# VPAC0_HTS_S_VBUSP register map
Vendor: Texas Instruments
Peripheral module from a debugger description file (folder J7ES).
Registers are 32-bit, read-write, reset 0x0 unless marked. A register's access mark holds for its fields unless they carry their own. Offsets are as the file gives them; lines under a group give offsets from that group; [hi:lo] are bit positions; {n}, {i} and the like mark numbered series; 'fields as' and 'values as' point back to an identical list; <NAME> marks a mode.

## VPAC0_HTS_S_VBUSP (part 1 of 2)
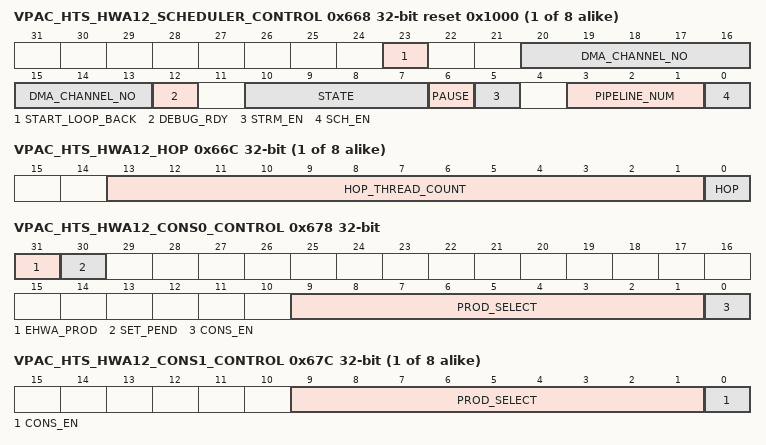
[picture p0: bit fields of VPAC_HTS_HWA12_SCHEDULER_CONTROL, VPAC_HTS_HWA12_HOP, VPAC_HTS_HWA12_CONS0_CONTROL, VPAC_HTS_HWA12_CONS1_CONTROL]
{0x188+0x68*i} VPAC_HTS_HWA{i}_SCHEDULER_CONTROL access per field reset 0x1000 (i=12..19) — Scheduler Control Register
  [23] START_LOOP_BACK rw — '1' -&gt; loop back start onto done in same cycle w/o asserting external channel start, '0' No loop back
  [20:13] DMA_CHANNEL_NO rw — DMA channel number for thread scheduler for HWA{i}
  [12] DEBUG_RDY rw — '0' -&gt; HWA{i} Scheduler resources must not be read during halted state.
  [10:7] STATE ro — Current state of HWA{i} Scheduler
  [6] PAUSE rw — '1' -&gt; pause/suspend scheduler , '0' -&gt; resume scheduler
  [5] STRM_EN rw — '1' -&gt; Streaming input enable, '0' No streaming input
  [3:1] PIPELINE_NUM rw — Pipeline Number of HWA{i} Scheduler
  [0] SCH_EN rw — scheduler enable
{0x18C+0x68*i} VPAC_HTS_HWA{i}_HOP (i=12..19) — Scheduler HOP Control Register. Help in detecting eop within scheduler. Once configured, it counts task/channel starts and stops issuing further starts. Specifically useful for Head of pipe dma scheduler .
  [13:1] HOP_THREAD_COUNT — Number of Task count for Head of pipe
  [0] HOP — '1' -&gt; Head of Pipe producer Sch , '0' -&gt; No hop
0x678 VPAC_HTS_HWA12_CONS0_CONTROL access per field — Controlling consumer socket 0 for HWA12
  [31] EHWA_PROD rw — '1' -&gt; spare consumer is connected to external host producer , '0' --&gt; no external host producer
  [30] SET_PEND wo — writing '1' sets pend on consumer socket
  [9:1] PROD_SELECT rw — producer select for HWA12 cons socket 0
  [0] CONS_EN rw — '1' -&gt; Consumer socket 0 enable , '0' Disable
{0x19C+0x68*i} VPAC_HTS_HWA{i}_CONS1_CONTROL (i=12..19) — Controlling consumer socket 1 for HWA{i}
  [9:1] PROD_SELECT — producer select for HWA{i} cons socket 1
  [0] CONS_EN — '1' -&gt; Consumer socket 1 enable , '0' Disable
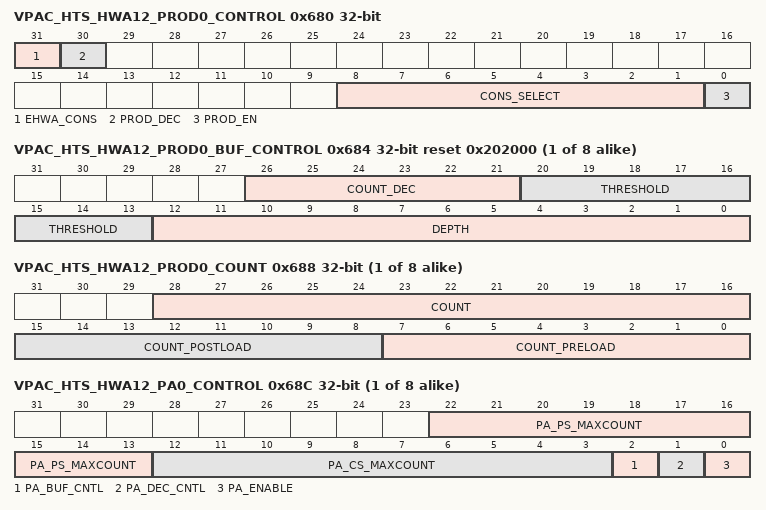
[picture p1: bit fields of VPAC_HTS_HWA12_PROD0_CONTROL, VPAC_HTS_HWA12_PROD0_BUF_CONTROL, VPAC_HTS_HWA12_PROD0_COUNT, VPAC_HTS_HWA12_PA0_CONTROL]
0x680 VPAC_HTS_HWA12_PROD0_CONTROL access per field — Controlling producer socket0 for HWA12
  [31] EHWA_CONS rw — '1' -&gt; spare consumer is connected to external host consumer , '0' --&gt; no external host consumer
  [30] PROD_DEC wo — writing '1' decrement prod count value
  [8:1] CONS_SELECT rw — consumer select for HWA12 prod socket 0.
  [0] PROD_EN rw — '1' -&gt; Producer socket 0 enable , '0' Disable
{0x1A4+0x68*i} VPAC_HTS_HWA{i}_PROD0_BUF_CONTROL reset 0x202000 (i=12..19) — Controlling producer socket0 buffer for HWA{i}
  [26:21] COUNT_DEC — Count decrement value for prod count
  [20:13] THRESHOLD — Count threshold to generate pend for consumer
  [12:0] DEPTH — Maximum number of producer buffer count
{0x1A8+0x68*i} VPAC_HTS_HWA{i}_PROD0_COUNT access per field (i=12..19) — Defining count values for pre/post load for generating pend by HWA{i} prod0
  [28:16] COUNT ro — current count value
  [15:8] COUNT_POSTLOAD rw — count postload after producer max thread count reached
  [7:0] COUNT_PRELOAD rw — count preload after scheduler start/init
{0x1AC+0x68*i} VPAC_HTS_HWA{i}_PA0_CONTROL (i=12..19) — control register to manage pattern adapter on HWA{i} prod socket0
  [22:13] PA_PS_MAXCOUNT — destination count for pattern adaptation (N), M --&gt; N
  [12:3] PA_CS_MAXCOUNT — source count for pattern adaptation (M), M --&gt; N
  [2] PA_BUF_CNTL — '1' -&gt; Apply threshold, count_preload and count_postload on pattern adapter count (use this only when pa_enable='1') '0' -&gt; Apply threshold, count_preload and count_postload on prod count (same behavior as if no pattern adapter.
  [1] PA_DEC_CNTL — '1' -&gt; post pattern adaptation, decrement ps count by count_dec , '0' -&gt; post pattern adaptation, decrement ps count by pa_cs_maxcount
  [0] PA_ENABLE — '1' -&gt; pa enable, '0' -&gt; disable
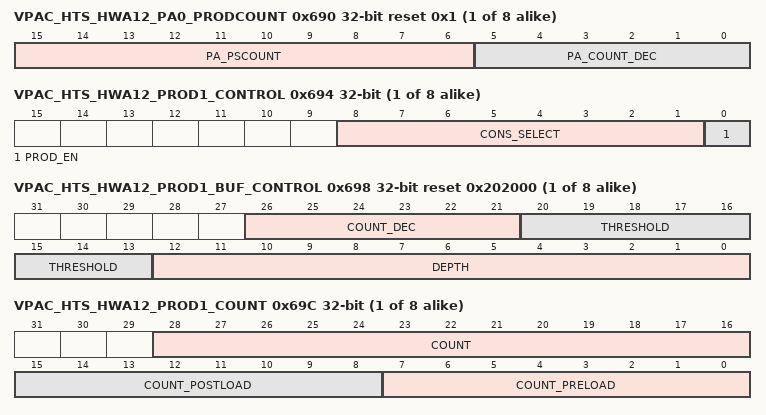
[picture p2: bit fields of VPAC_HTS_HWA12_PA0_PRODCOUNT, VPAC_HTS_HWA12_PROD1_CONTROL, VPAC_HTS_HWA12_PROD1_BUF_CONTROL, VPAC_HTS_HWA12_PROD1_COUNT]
{0x1B0+0x68*i} VPAC_HTS_HWA{i}_PA0_PRODCOUNT access per field reset 0x1 (i=12..19) — count values for HWA{i} prod socket0
  [15:6] PA_PSCOUNT ro — current count value of pa prod count
  [5:0] PA_COUNT_DEC rw — Decrement count value of pa_prod_count after pattern adapter prod count reaches threshold
{0x1B4+0x68*i} VPAC_HTS_HWA{i}_PROD1_CONTROL (i=12..19) — Controlling producer socket1 for HWA{i}
  [8:1] CONS_SELECT — consumer select for HWA{i} prod socket 1.
  [0] PROD_EN — '1' -&gt; Producer socket 0 enable , '0' Disable
{0x1B8+0x68*i} VPAC_HTS_HWA{i}_PROD1_BUF_CONTROL reset 0x202000 (i=12..19) — Controlling producer socket1 buffer for HWA{i}
  fields as VPAC_HTS_HWA12_PROD0_BUF_CONTROL
{0x1BC+0x68*i} VPAC_HTS_HWA{i}_PROD1_COUNT access per field (i=12..19) — Defining count values for pre/post load for generating pend by HWA{i} prod1
  fields as VPAC_HTS_HWA12_PROD0_COUNT
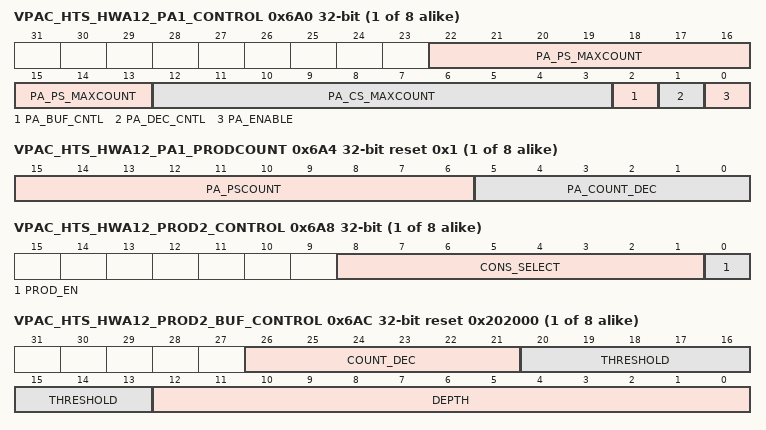
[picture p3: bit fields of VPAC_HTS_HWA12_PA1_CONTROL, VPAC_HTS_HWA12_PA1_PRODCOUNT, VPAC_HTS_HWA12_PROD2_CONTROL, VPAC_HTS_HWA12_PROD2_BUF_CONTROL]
{0x1C0+0x68*i} VPAC_HTS_HWA{i}_PA1_CONTROL (i=12..19) — control register to manage pattern adapter on HWA{i} prod socket1
  fields as VPAC_HTS_HWA12_PA0_CONTROL
{0x1C4+0x68*i} VPAC_HTS_HWA{i}_PA1_PRODCOUNT access per field reset 0x1 (i=12..19) — count values for HWA{i} prod socket1
  fields as VPAC_HTS_HWA12_PA0_PRODCOUNT
{0x1C8+0x68*i} VPAC_HTS_HWA{i}_PROD2_CONTROL (i=12..19) — Controlling producer socket2 for HWA{i}
  [8:1] CONS_SELECT — consumer select for HWA{i} prod socket 2.
  [0] PROD_EN — '1' -&gt; Producer socket 0 enable , '0' Disable
{0x1CC+0x68*i} VPAC_HTS_HWA{i}_PROD2_BUF_CONTROL reset 0x202000 (i=12..19) — Controlling producer socket2 buffer for HWA{i}
  fields as VPAC_HTS_HWA12_PROD0_BUF_CONTROL
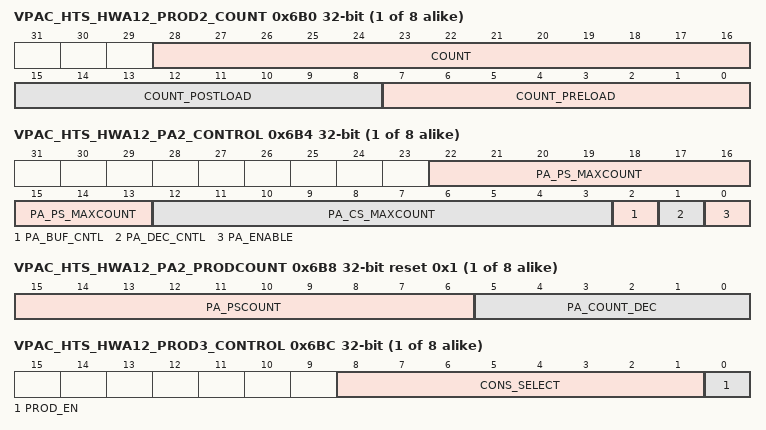
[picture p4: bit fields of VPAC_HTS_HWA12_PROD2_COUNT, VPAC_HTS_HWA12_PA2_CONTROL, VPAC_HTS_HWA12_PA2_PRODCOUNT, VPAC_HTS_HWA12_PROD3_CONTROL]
{0x1D0+0x68*i} VPAC_HTS_HWA{i}_PROD2_COUNT access per field (i=12..19) — Defining count values for pre/post load for generating pend by HWA{i} prod2
  fields as VPAC_HTS_HWA12_PROD0_COUNT
{0x1D4+0x68*i} VPAC_HTS_HWA{i}_PA2_CONTROL (i=12..19) — control register to manage pattern adapter on HWA{i} prod socket2
  fields as VPAC_HTS_HWA12_PA0_CONTROL
{0x1D8+0x68*i} VPAC_HTS_HWA{i}_PA2_PRODCOUNT access per field reset 0x1 (i=12..19) — count values for HWA{i} prod socket2
  fields as VPAC_HTS_HWA12_PA0_PRODCOUNT
{0x1DC+0x68*i} VPAC_HTS_HWA{i}_PROD3_CONTROL (i=12..19) — Controlling producer socket3 for HWA{i}
  [8:1] CONS_SELECT — consumer select for HWA{i} prod socket 3.
  [0] PROD_EN — '1' -&gt; Producer socket 0 enable , '0' Disable
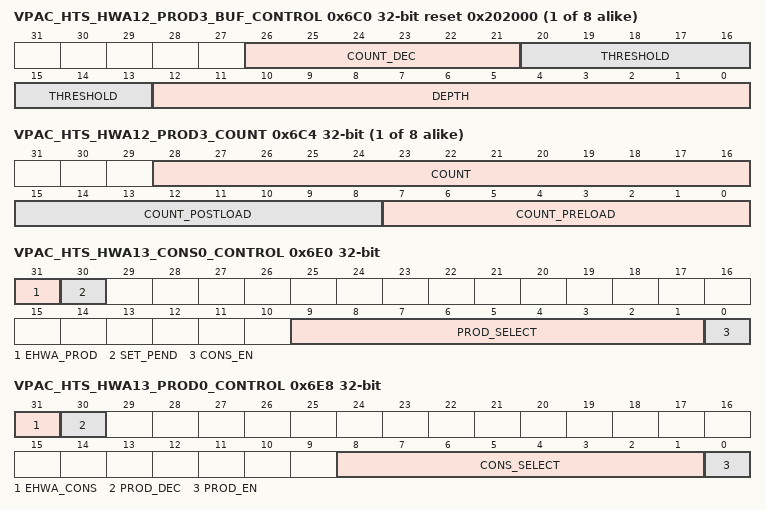
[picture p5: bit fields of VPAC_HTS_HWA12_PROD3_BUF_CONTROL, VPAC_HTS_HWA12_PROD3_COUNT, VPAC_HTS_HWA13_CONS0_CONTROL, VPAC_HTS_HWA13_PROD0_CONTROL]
{0x1E0+0x68*i} VPAC_HTS_HWA{i}_PROD3_BUF_CONTROL reset 0x202000 (i=12..19) — Controlling producer socket3 buffer for HWA{i}
  fields as VPAC_HTS_HWA12_PROD0_BUF_CONTROL
{0x1E4+0x68*i} VPAC_HTS_HWA{i}_PROD3_COUNT access per field (i=12..19) — Defining count values for pre/post load for generating pend by HWA{i} prod3
  fields as VPAC_HTS_HWA12_PROD0_COUNT
0x6E0 VPAC_HTS_HWA13_CONS0_CONTROL access per field — Controlling consumer socket 0 for HWA13
  [31] EHWA_PROD rw — '1' -&gt; spare consumer is connected to external host producer , '0' --&gt; no external host producer
  [30] SET_PEND wo — writing '1' sets pend on consumer socket
  [9:1] PROD_SELECT rw — producer select for HWA13 cons socket 0
  [0] CONS_EN rw — '1' -&gt; Consumer socket 0 enable , '0' Disable
0x6E8 VPAC_HTS_HWA13_PROD0_CONTROL access per field — Controlling producer socket0 for HWA13
  [31] EHWA_CONS rw — '1' -&gt; spare consumer is connected to external host consumer , '0' --&gt; no external host consumer
  [30] PROD_DEC wo — writing '1' decrement prod count value
  [8:1] CONS_SELECT rw — consumer select for HWA13 prod socket 0.
  [0] PROD_EN rw — '1' -&gt; Producer socket 0 enable , '0' Disable
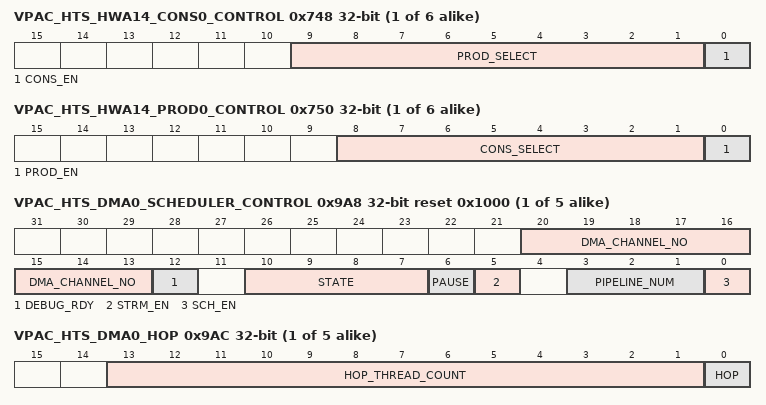
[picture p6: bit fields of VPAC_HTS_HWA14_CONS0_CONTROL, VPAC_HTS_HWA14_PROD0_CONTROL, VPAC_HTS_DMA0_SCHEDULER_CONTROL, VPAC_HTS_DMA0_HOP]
{0x198+0x68*i} VPAC_HTS_HWA{i}_CONS0_CONTROL (i=14..19) — Controlling consumer socket 0 for HWA{i}
  [9:1] PROD_SELECT — producer select for HWA{i} cons socket 0
  [0] CONS_EN — '1' -&gt; Consumer socket 0 enable , '0' Disable
{0x1A0+0x68*i} VPAC_HTS_HWA{i}_PROD0_CONTROL (i=14..19) — Controlling producer socket0 for HWA{i}
  [8:1] CONS_SELECT — consumer select for HWA{i} prod socket 0.
  [0] PROD_EN — '1' -&gt; Producer socket 0 enable , '0' Disable
{0x9A8+0x1C*i} VPAC_HTS_DMA{i}_SCHEDULER_CONTROL access per field reset 0x1000 (i=0..4) — Scheduler Control Register
  [20:13] DMA_CHANNEL_NO rw — DMA channel number for thread scheduler for DMA{i}
  [12] DEBUG_RDY rw — '0' -&gt; DMA{i} Scheduler resources must not be read during halted state.
  [10:7] STATE ro — Current state of DMA{i} Scheduler
  [6] PAUSE rw — '1' -&gt; pause/suspend scheduler , '0' -&gt; resume scheduler
  [5] STRM_EN rw — '1' -&gt; Streaming input enable, '0' No streaming input
  [3:1] PIPELINE_NUM rw — Pipeline Number of DMA{i} Scheduler
  [0] SCH_EN rw — scheduler enable
{0x9AC+0x1C*i} VPAC_HTS_DMA{i}_HOP (i=0..4) — Scheduler HOP Control Register. Help in detecting eop within scheduler. Once configured, it counts task/channel starts and stops issuing further starts. Specifically useful for Head of pipe dma scheduler .
  fields as VPAC_HTS_HWA12_HOP
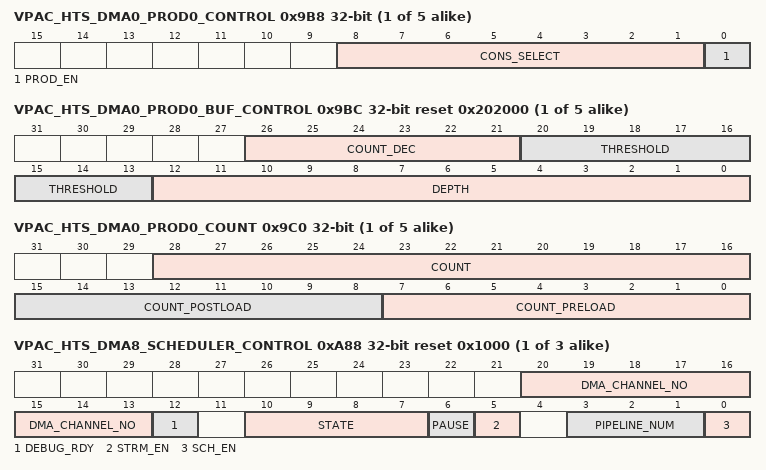
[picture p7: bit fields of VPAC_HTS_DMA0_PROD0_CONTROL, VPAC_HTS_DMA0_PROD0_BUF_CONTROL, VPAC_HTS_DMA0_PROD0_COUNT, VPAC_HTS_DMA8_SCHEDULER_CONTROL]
{0x9B8+0x1C*i} VPAC_HTS_DMA{i}_PROD0_CONTROL (i=0..4) — Controlling producer socket0 for DMA{i}
  [8:1] CONS_SELECT — consumer select for DMA{i} prod socket 0.
  [0] PROD_EN — '1' -&gt; Producer socket 0 enable , '0' Disable
{0x9BC+0x1C*i} VPAC_HTS_DMA{i}_PROD0_BUF_CONTROL reset 0x202000 (i=0..4) — Controlling producer socket0 buffer for DMA{i}
  fields as VPAC_HTS_HWA12_PROD0_BUF_CONTROL
{0x9C0+0x1C*i} VPAC_HTS_DMA{i}_PROD0_COUNT access per field (i=0..4) — Defining count values for pre/post load for generating pend by DMA{i} prod0
  fields as VPAC_HTS_HWA12_PROD0_COUNT
{0x968+0x24*i} VPAC_HTS_DMA{i}_SCHEDULER_CONTROL access per field reset 0x1000 (i=8..10) — Scheduler Control Register
  fields as VPAC_HTS_DMA0_SCHEDULER_CONTROL
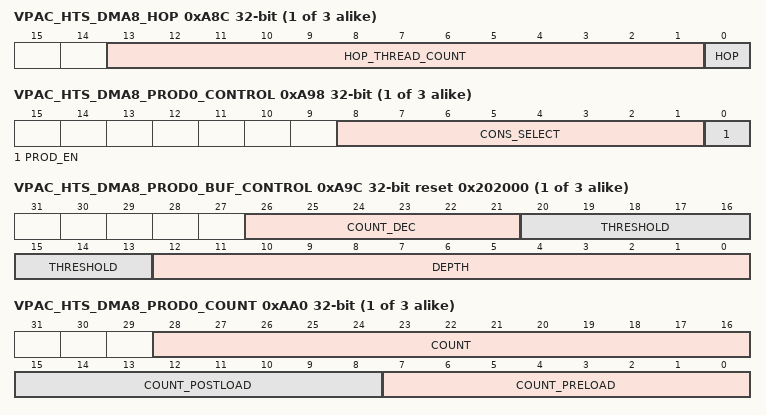
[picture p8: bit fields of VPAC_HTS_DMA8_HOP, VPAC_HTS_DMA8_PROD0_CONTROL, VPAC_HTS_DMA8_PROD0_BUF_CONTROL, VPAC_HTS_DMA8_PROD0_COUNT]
{0x96C+0x24*i} VPAC_HTS_DMA{i}_HOP (i=8..10) — Scheduler HOP Control Register. Help in detecting eop within scheduler. Once configured, it counts task/channel starts and stops issuing further starts. Specifically useful for Head of pipe dma scheduler .
  fields as VPAC_HTS_HWA12_HOP
{0x978+0x24*i} VPAC_HTS_DMA{i}_PROD0_CONTROL (i=8..10) — Controlling producer socket0 for DMA{i}
  fields as VPAC_HTS_DMA0_PROD0_CONTROL
{0x97C+0x24*i} VPAC_HTS_DMA{i}_PROD0_BUF_CONTROL reset 0x202000 (i=8..10) — Controlling producer socket0 buffer for DMA{i}
  fields as VPAC_HTS_HWA12_PROD0_BUF_CONTROL
{0x980+0x24*i} VPAC_HTS_DMA{i}_PROD0_COUNT access per field (i=8..10) — Defining count values for pre/post load for generating pend by DMA{i} prod0
  fields as VPAC_HTS_HWA12_PROD0_COUNT
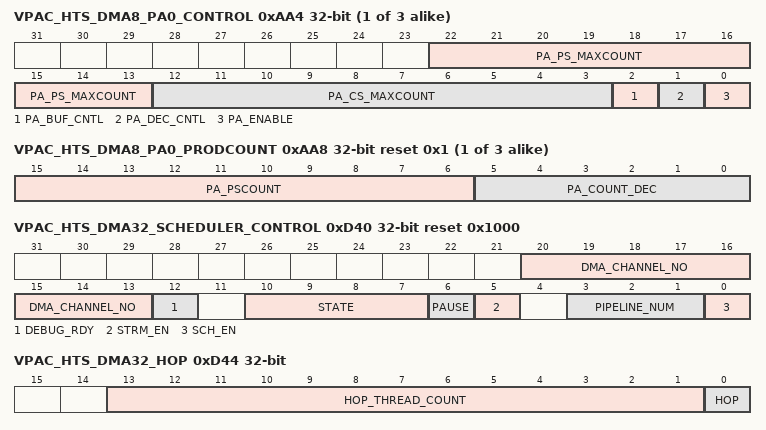
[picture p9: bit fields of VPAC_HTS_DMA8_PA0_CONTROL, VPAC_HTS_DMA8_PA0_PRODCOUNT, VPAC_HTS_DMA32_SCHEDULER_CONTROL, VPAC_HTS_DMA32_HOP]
{0x984+0x24*i} VPAC_HTS_DMA{i}_PA0_CONTROL (i=8..10) — control register to manage pattern adapter on DMA{i} prod socket0
  fields as VPAC_HTS_HWA12_PA0_CONTROL
{0x988+0x24*i} VPAC_HTS_DMA{i}_PA0_PRODCOUNT access per field reset 0x1 (i=8..10) — count values for HWA{i} prod socket0
  fields as VPAC_HTS_HWA12_PA0_PRODCOUNT
0xD40 VPAC_HTS_DMA32_SCHEDULER_CONTROL access per field reset 0x1000 — Scheduler Control Register
  [20:13] DMA_CHANNEL_NO rw — DMA channel number for thread scheduler for DMA32
  [12] DEBUG_RDY rw — '0' -&gt; DMA32 Scheduler resources must not be read during halted state.
  [10:7] STATE ro — Current state of DMA32 Scheduler
  [6] PAUSE rw — '1' -&gt; pause/suspend scheduler , '0' -&gt; resume scheduler
  [5] STRM_EN rw — '1' -&gt; Streaming input enable, '0' No streaming input
  [3:1] PIPELINE_NUM rw — Pipeline Number of DMA32 Scheduler
  [0] SCH_EN rw — scheduler enable
0xD44 VPAC_HTS_DMA32_HOP — Scheduler HOP Control Register. Help in detecting eop within scheduler. Once configured, it counts task/channel starts and stops issuing further starts. Specifically useful for Head of pipe dma scheduler .
  fields as VPAC_HTS_HWA12_HOP
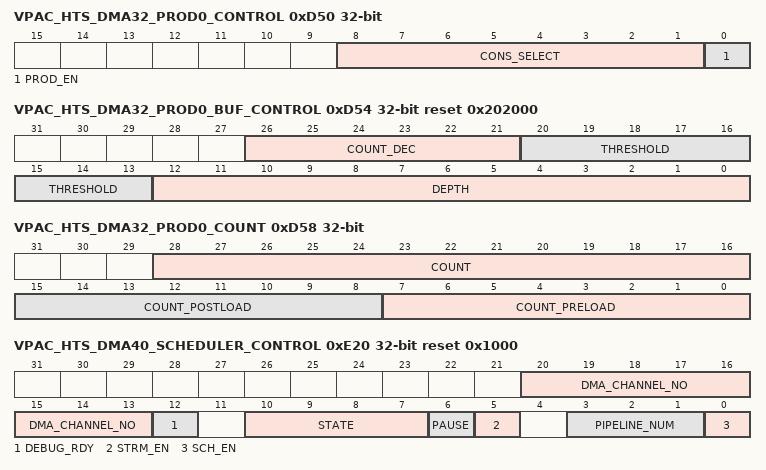
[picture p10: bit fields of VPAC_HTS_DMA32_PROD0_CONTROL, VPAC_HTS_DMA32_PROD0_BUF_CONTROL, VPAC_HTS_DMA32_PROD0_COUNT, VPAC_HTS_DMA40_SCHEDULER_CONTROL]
0xD50 VPAC_HTS_DMA32_PROD0_CONTROL — Controlling producer socket0 for DMA32
  [8:1] CONS_SELECT — consumer select for DMA32 prod socket 0.
  [0] PROD_EN — '1' -&gt; Producer socket 0 enable , '0' Disable
0xD54 VPAC_HTS_DMA32_PROD0_BUF_CONTROL reset 0x202000 — Controlling producer socket0 buffer for DMA32
  fields as VPAC_HTS_HWA12_PROD0_BUF_CONTROL
0xD58 VPAC_HTS_DMA32_PROD0_COUNT access per field — Defining count values for pre/post load for generating pend by DMA32 prod0
  fields as VPAC_HTS_HWA12_PROD0_COUNT
0xE20 VPAC_HTS_DMA40_SCHEDULER_CONTROL access per field reset 0x1000 — Scheduler Control Register
  [20:13] DMA_CHANNEL_NO rw — DMA channel number for thread scheduler for DMA40
  [12] DEBUG_RDY rw — '0' -&gt; DMA40 Scheduler resources must not be read during halted state.
  [10:7] STATE ro — Current state of DMA40 Scheduler
  [6] PAUSE rw — '1' -&gt; pause/suspend scheduler , '0' -&gt; resume scheduler
  [5] STRM_EN rw — '1' -&gt; Streaming input enable, '0' No streaming input
  [3:1] PIPELINE_NUM rw — Pipeline Number of DMA40 Scheduler
  [0] SCH_EN rw — scheduler enable
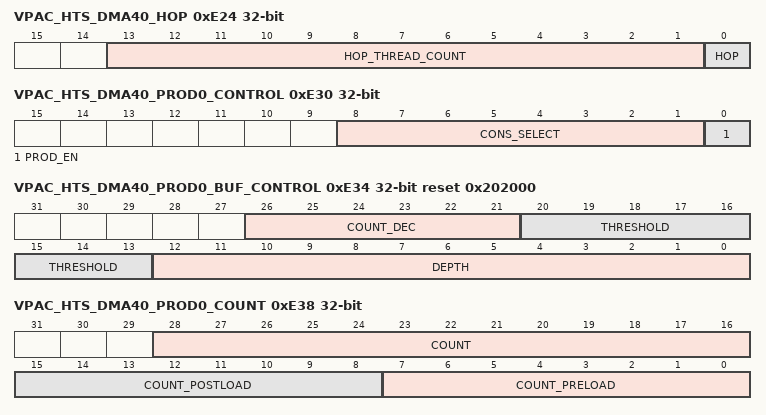
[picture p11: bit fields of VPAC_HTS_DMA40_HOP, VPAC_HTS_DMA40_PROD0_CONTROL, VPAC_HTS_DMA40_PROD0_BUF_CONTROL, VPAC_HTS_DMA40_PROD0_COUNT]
0xE24 VPAC_HTS_DMA40_HOP — Scheduler HOP Control Register. Help in detecting eop within scheduler. Once configured, it counts task/channel starts and stops issuing further starts. Specifically useful for Head of pipe dma scheduler .
  fields as VPAC_HTS_HWA12_HOP
0xE30 VPAC_HTS_DMA40_PROD0_CONTROL — Controlling producer socket0 for DMA40
  [8:1] CONS_SELECT — consumer select for DMA40 prod socket 0.
  [0] PROD_EN — '1' -&gt; Producer socket 0 enable , '0' Disable
0xE34 VPAC_HTS_DMA40_PROD0_BUF_CONTROL reset 0x202000 — Controlling producer socket0 buffer for DMA40
  fields as VPAC_HTS_HWA12_PROD0_BUF_CONTROL
0xE38 VPAC_HTS_DMA40_PROD0_COUNT access per field — Defining count values for pre/post load for generating pend by DMA40 prod0
  fields as VPAC_HTS_HWA12_PROD0_COUNT
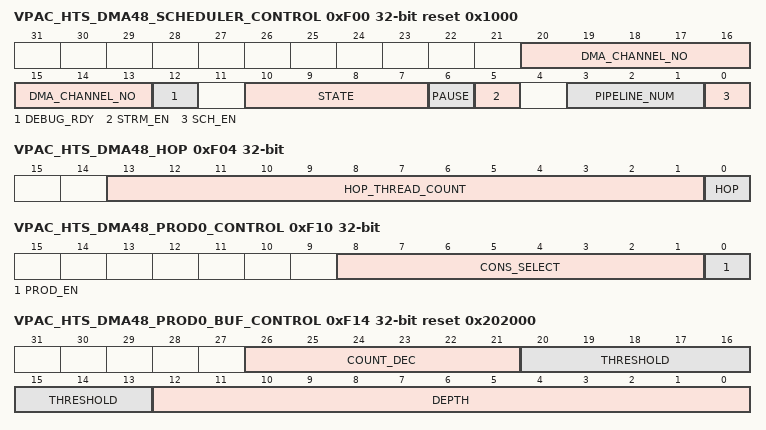
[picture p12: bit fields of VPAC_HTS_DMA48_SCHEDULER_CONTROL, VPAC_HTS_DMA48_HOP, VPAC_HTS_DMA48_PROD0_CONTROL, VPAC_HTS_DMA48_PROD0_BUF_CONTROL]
0xF00 VPAC_HTS_DMA48_SCHEDULER_CONTROL access per field reset 0x1000 — Scheduler Control Register
  [20:13] DMA_CHANNEL_NO rw — DMA channel number for thread scheduler for DMA48
  [12] DEBUG_RDY rw — '0' -&gt; DMA48 Scheduler resources must not be read during halted state.
  [10:7] STATE ro — Current state of DMA48 Scheduler
  [6] PAUSE rw — '1' -&gt; pause/suspend scheduler , '0' -&gt; resume scheduler
  [5] STRM_EN rw — '1' -&gt; Streaming input enable, '0' No streaming input
  [3:1] PIPELINE_NUM rw — Pipeline Number of DMA48 Scheduler
  [0] SCH_EN rw — scheduler enable
0xF04 VPAC_HTS_DMA48_HOP — Scheduler HOP Control Register. Help in detecting eop within scheduler. Once configured, it counts task/channel starts and stops issuing further starts. Specifically useful for Head of pipe dma scheduler .
  fields as VPAC_HTS_HWA12_HOP
0xF10 VPAC_HTS_DMA48_PROD0_CONTROL — Controlling producer socket0 for DMA48
  [8:1] CONS_SELECT — consumer select for DMA48 prod socket 0.
  [0] PROD_EN — '1' -&gt; Producer socket 0 enable , '0' Disable
0xF14 VPAC_HTS_DMA48_PROD0_BUF_CONTROL reset 0x202000 — Controlling producer socket0 buffer for DMA48
  fields as VPAC_HTS_HWA12_PROD0_BUF_CONTROL
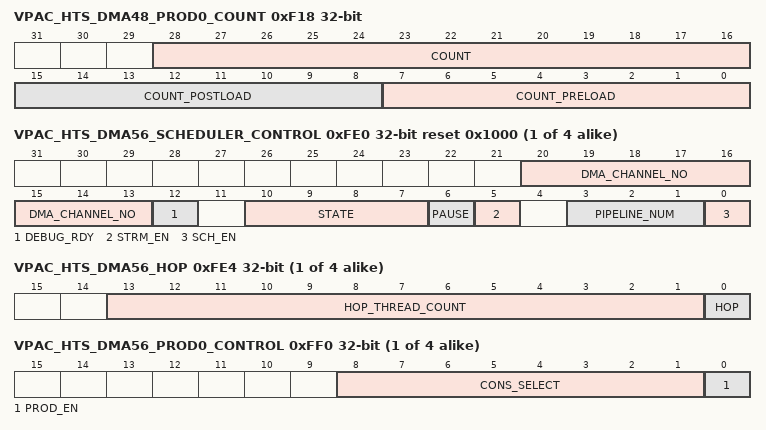
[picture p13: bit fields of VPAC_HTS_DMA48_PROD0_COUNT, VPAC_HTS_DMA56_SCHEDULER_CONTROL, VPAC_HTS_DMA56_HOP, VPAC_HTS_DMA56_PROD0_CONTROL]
0xF18 VPAC_HTS_DMA48_PROD0_COUNT access per field — Defining count values for pre/post load for generating pend by DMA48 prod0
  fields as VPAC_HTS_HWA12_PROD0_COUNT
{0x9C0+0x1C*i} VPAC_HTS_DMA{i}_SCHEDULER_CONTROL access per field reset 0x1000 (i=56..59) — Scheduler Control Register
  fields as VPAC_HTS_DMA0_SCHEDULER_CONTROL
{0x9C4+0x1C*i} VPAC_HTS_DMA{i}_HOP (i=56..59) — Scheduler HOP Control Register. Help in detecting eop within scheduler. Once configured, it counts task/channel starts and stops issuing further starts. Specifically useful for Head of pipe dma scheduler .
  fields as VPAC_HTS_HWA12_HOP
{0x9D0+0x1C*i} VPAC_HTS_DMA{i}_PROD0_CONTROL (i=56..59) — Controlling producer socket0 for DMA{i}
  fields as VPAC_HTS_DMA0_PROD0_CONTROL
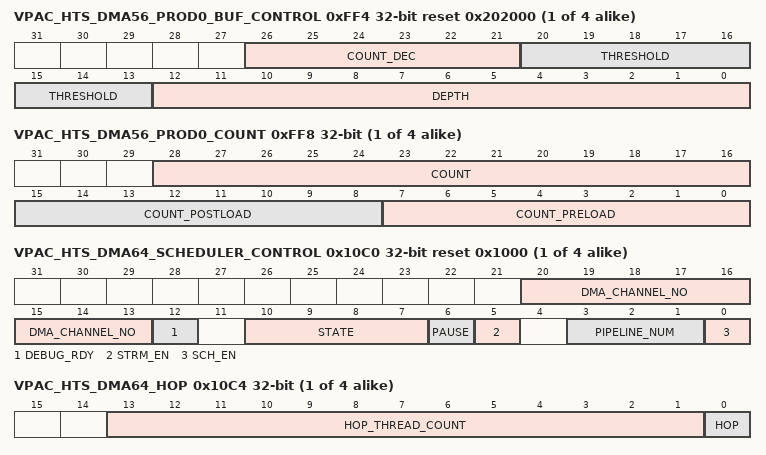
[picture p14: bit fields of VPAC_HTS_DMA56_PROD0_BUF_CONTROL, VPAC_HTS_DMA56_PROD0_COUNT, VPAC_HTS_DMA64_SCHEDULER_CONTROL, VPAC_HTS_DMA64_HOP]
{0x9D4+0x1C*i} VPAC_HTS_DMA{i}_PROD0_BUF_CONTROL reset 0x202000 (i=56..59) — Controlling producer socket0 buffer for DMA{i}
  fields as VPAC_HTS_HWA12_PROD0_BUF_CONTROL
{0x9D8+0x1C*i} VPAC_HTS_DMA{i}_PROD0_COUNT access per field (i=56..59) — Defining count values for pre/post load for generating pend by DMA{i} prod0
  fields as VPAC_HTS_HWA12_PROD0_COUNT
{0x9C0+0x1C*i} VPAC_HTS_DMA{i}_SCHEDULER_CONTROL access per field reset 0x1000 (i=64..67) — Scheduler Control Register
  fields as VPAC_HTS_DMA0_SCHEDULER_CONTROL
{0x9C4+0x1C*i} VPAC_HTS_DMA{i}_HOP (i=64..67) — Scheduler HOP Control Register. Help in detecting eop within scheduler. Once configured, it counts task/channel starts and stops issuing further starts. Specifically useful for Head of pipe dma scheduler .
  fields as VPAC_HTS_HWA12_HOP
{0x9D0+0x1C*i} VPAC_HTS_DMA{i}_PROD0_CONTROL (i=64..67) — Controlling producer socket0 for DMA{i}
  fields as VPAC_HTS_DMA0_PROD0_CONTROL
{0x9D4+0x1C*i} VPAC_HTS_DMA{i}_PROD0_BUF_CONTROL reset 0x202000 (i=64..67) — Controlling producer socket0 buffer for DMA{i}
  fields as VPAC_HTS_HWA12_PROD0_BUF_CONTROL
{0x9D8+0x1C*i} VPAC_HTS_DMA{i}_PROD0_COUNT access per field (i=64..67) — Defining count values for pre/post load for generating pend by DMA{i} prod0
  fields as VPAC_HTS_HWA12_PROD0_COUNT
{0xEF4+0x14*i} VPAC_HTS_DMA{i}_SCHEDULER_CONTROL access per field reset 0x1000 (i=240..245) — Scheduler Control Register
  fields as VPAC_HTS_DMA0_SCHEDULER_CONTROL
{0xF04+0x14*i} VPAC_HTS_DMA{i}_CONS0_CONTROL (i=240..245) — Controlling consumer socket 0 for DMA{i}
  [9:1] PROD_SELECT — producer select for DMA{i} cons socket 0
  [0] CONS_EN — '1' -&gt; Consumer socket 0 enable , '0' Disable
{0xE2C+0x14*i} VPAC_HTS_DMA{i}_SCHEDULER_CONTROL access per field reset 0x1000 (i=256..261) — Scheduler Control Register
  fields as VPAC_HTS_DMA0_SCHEDULER_CONTROL
{0xE3C+0x14*i} VPAC_HTS_DMA{i}_CONS0_CONTROL (i=256..261) — Controlling consumer socket 0 for DMA{i}
  fields as VPAC_HTS_DMA240_CONS0_CONTROL
{0xD64+0x14*i} VPAC_HTS_DMA{i}_SCHEDULER_CONTROL access per field reset 0x1000 (i=272..275) — Scheduler Control Register
  fields as VPAC_HTS_DMA0_SCHEDULER_CONTROL
{0xD74+0x14*i} VPAC_HTS_DMA{i}_CONS0_CONTROL (i=272..275) — Controlling consumer socket 0 for DMA{i}
  fields as VPAC_HTS_DMA240_CONS0_CONTROL
{0xC74+0x14*i} VPAC_HTS_DMA{i}_SCHEDULER_CONTROL access per field reset 0x1000 (i=288..291) — Scheduler Control Register
  fields as VPAC_HTS_DMA0_SCHEDULER_CONTROL
{0xC84+0x14*i} VPAC_HTS_DMA{i}_CONS0_CONTROL (i=288..291) — Controlling consumer socket 0 for DMA{i}
  fields as VPAC_HTS_DMA240_CONS0_CONTROL
{0xB84+0x14*i} VPAC_HTS_DMA{i}_SCHEDULER_CONTROL access per field reset 0x1000 (i=304..313) — Scheduler Control Register
  fields as VPAC_HTS_DMA0_SCHEDULER_CONTROL
{0xB94+0x14*i} VPAC_HTS_DMA{i}_CONS0_CONTROL (i=304..313) — Controlling consumer socket 0 for DMA{i}
  fields as VPAC_HTS_DMA240_CONS0_CONTROL
0x240C VPAC_HTS_DMA336_SCHEDULER_CONTROL access per field reset 0x1000 — Scheduler Control Register
  [20:13] DMA_CHANNEL_NO rw — DMA channel number for thread scheduler for DMA336
  [12] DEBUG_RDY rw — '0' -&gt; DMA336 Scheduler resources must not be read during halted state.
  [10:7] STATE ro — Current state of DMA336 Scheduler
  [6] PAUSE rw — '1' -&gt; pause/suspend scheduler , '0' -&gt; resume scheduler
  [5] STRM_EN rw — '1' -&gt; Streaming input enable, '0' No streaming input
  [3:1] PIPELINE_NUM rw — Pipeline Number of DMA336 Scheduler
  [0] SCH_EN rw — scheduler enable
0x241C VPAC_HTS_DMA336_CONS0_CONTROL — Controlling consumer socket 0 for DMA336
  [9:1] PROD_SELECT — producer select for DMA336 cons socket 0
  [0] CONS_EN — '1' -&gt; Consumer socket 0 enable , '0' Disable
{0x8A0+0x14*i} VPAC_HTS_DMA{i}_SCHEDULER_CONTROL access per field reset 0x1000 (i=352..355) — Scheduler Control Register
  fields as VPAC_HTS_DMA0_SCHEDULER_CONTROL
{0x8B0+0x14*i} VPAC_HTS_DMA{i}_CONS0_CONTROL (i=352..355) — Controlling consumer socket 0 for DMA{i}
  fields as VPAC_HTS_DMA240_CONS0_CONTROL
{0x7B0+0x14*i} VPAC_HTS_DMA{i}_SCHEDULER_CONTROL access per field reset 0x1000 (i=368..371) — Scheduler Control Register
  fields as VPAC_HTS_DMA0_SCHEDULER_CONTROL
{0x7C0+0x14*i} VPAC_HTS_DMA{i}_CONS0_CONTROL (i=368..371) — Controlling consumer socket 0 for DMA{i}
  fields as VPAC_HTS_DMA240_CONS0_CONTROL
0x2650 VPAC_HTS_PIPE_DBG_CNTL access per field — Pipeline Debug Control register is used by debug software to control pipeline debug behavior
  [19:17] DEBUG_STATE ro — Current state of Debug activity
  [16] ABORT_DEBUG wo — '1' -&gt; Abort Debug activity on debug enabled pipelines, '0' no impact
  [6] PIPE_DBG_DIS_6 rw — '1' -&gt; Pipeline6 doesn't respond to debug events, '0' Pipeline5 respond to debug events
  [n] PIPE_DBG_DIS_{n} rw (n=0..5) — '1' -&gt; Pipeline{n} doesn't respond to debug events, '0' Pipeline{n} respond to debug events
0x2654 VPAC_HTS_DBG_CAP ro reset 0xD00020 — Debug Capability register is used by debug software to determine which optional debug modules are present and how many instances of each module exist.
  [30] DBG_INT_STEP_SUP — Indicates that debug execution control can determine if single step blocks or allows interrupts.
  [29] DBG_WP_DATA_SUP — Indicates if the WP resources has corresponding data qualification.
  [28] DBG_OWN_SUP — Indicates if the HWA supports an module ownership.
  [27] DBG_INDIRECT_SUP — Indicates if the HWA supports an indirect memory access port.
  [26] DBG_SWBP_SUP — Whether HWA Core supports SWBP or not.
  [25] DBQ_RESET_SUP — Whether HWA Core reset is supported or not which does not affect debug logic.
  [24] SYS_EXE_REQ — Whether HWA Core Execution status and control is supported.
  [23] TRIG_OUTPUT — b
  [22] TRIG_INPUT — b
  [21:20] TRIG_CHNS — Number of Trigger Channels Supported.
  [19:16] NUM_CNTRS — The number of counter modules that exist.
  [15:12] NUM_WPS — The number of watchpoint modules that exist.
  [11:8] NUM_BPS — The number of breakpoint modules that exist.
  [7:4] REV_MAJ — Major Revision
  [3:0] REV_MIN — Minor Revision
0x2658 VPAC_HTS_DBG_CNTL access not given — Debug Control register is used by debug software to control all of the basic debug functions.
  [26] DBG_RESET_OCC — Sticky status bit to reflect reset has been generated (access RW1C)
  [19:16] DBG_EMU0_CNTL rw — EMU0 output control.
  [12] DBG_HALT_EMU0 ro — Execution halted due to trigger in on EMU0 input Set to '1' when halt due to EMU0 input completes Set to '0' when execution resumes
  [11] DBG_HALT_USER ro — Execution halted due to register update of DBG_HALT Set to '1' when halt due to DBG_HALT update completes Set to '0' when execution resumes
  [10] DBG_HALT_STEP ro — Execution halted due to single step completion Set to '1' when the single step completes Set to '0' when execution resumes
  [7] DBG_EXE_STAT ro — The execution status of the module Set to '1' when halted due to debug event Set to '0' when execution resumes
  [5] DBG_EMU0_EN rw — EMU0 input trigger enable Writing '1' enables halting on the falling edge of the EMU0 input Writing '0' disables halts via EMU0 input
  [2] DBG_SINGLE_STEP_EN rw — Single Step Execution enable.
  [1] DBG_RESTART rw — Debug Restart Status bit.This bit is normally set when the DBG_HALT bit transitions from '1' to '0' when the natural execution state is entered.It is a sticky bit.
  [0] DBG_HALT rw — Global debug run control.
